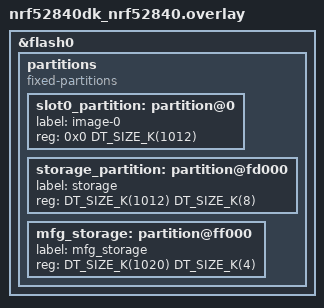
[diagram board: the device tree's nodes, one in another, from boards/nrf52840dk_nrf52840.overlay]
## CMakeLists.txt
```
#
# Copyright (c) 2026 Nordic Semiconductor ASA
#
# SPDX-License-Identifier: LicenseRef-Nordic-5-Clause
#

cmake_minimum_required(VERSION 3.20.0)

# Zephyr CMake project
find_package(Zephyr REQUIRED HINTS $ENV{ZEPHYR_BASE})
project(sidewalk_lr11xx_firmware_update)

# Source files
target_include_directories(app PRIVATE include)
target_sources(app PRIVATE
	src/main.c
	src/app.c
	src/lr11xx_firmware_update.c
)

if(CONFIG_SIDEWALK_SUBGHZ_RADIO_LR1110)
	target_include_directories(app PRIVATE
		${ZEPHYR_SIDEWALK_MODULE_DIR}/subsys/semtech/lr11xx
		${ZEPHYR_SIDEWALK_MODULE_DIR}/subsys/semtech/lr11xx/semtech
	)
	target_link_libraries(app PRIVATE
		smtc_lbm
		semtech_radio_ifc
	)
endif()

if(CONFIG_SIDEWALK_USE_PREBUILT_LIBRARIES)
	target_link_libraries(app PRIVATE sidewalk)
endif()
```

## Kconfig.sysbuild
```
#
# Copyright (c) 2023 Nordic Semiconductor ASA
#
# SPDX-License-Identifier: LicenseRef-Nordic-5-Clause
#

choice BOOTLOADER
	default BOOTLOADER_NONE
endchoice

source "${ZEPHYR_BASE}/share/sysbuild/Kconfig"
```

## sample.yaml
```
sample:
  name: LR11xx firmware update sample
  description: Sample for updating Semtech LR11xx transceiver firmware

common:
  sysbuild: true
  build_only: true
  tags:
    - Sidewalk
    - lr1110

tests:
  sample.lr11xx_firmware_update.lr1110:
    platform_allow:
      - nrf54l15dk/nrf54l15/cpuapp
    integration_platforms:
      - nrf54l15dk/nrf54l15/cpuapp
    extra_args:
      - SHIELD="simple_arduino_adapter;semtech_lr1110mb1xxs"

  sample.lr11xx_firmware_update.nrf_sidewalk_eb:
    platform_allow:
      - nrf54l15dk/nrf54l15/cpuapp
      - nrf54lm20dk/nrf54lm20a/cpuapp
      - nrf54lm20dk/nrf54lm20b/cpuapp
    integration_platforms:
      - nrf54l15dk/nrf54l15/cpuapp
      - nrf54lm20dk/nrf54lm20a/cpuapp
      - nrf54lm20dk/nrf54lm20b/cpuapp
    extra_args:
      - SHIELD="nrf_sidewalk_eb"
```

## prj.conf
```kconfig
#
# Copyright (c) 2026 Nordic Semiconductor ASA
#
# SPDX-License-Identifier: LicenseRef-Nordic-5-Clause
#

CONFIG_STATIC_INIT_GNU=y

# Sidewalk platform (radio PAL only, no DFU/bootloader)
CONFIG_SIDEWALK=y
CONFIG_SIDEWALK_DFU=n

# Log
CONFIG_LOG=y
CONFIG_LOG_PRINTK=y
CONFIG_LOG_BUFFER_SIZE=2048

# Stack and Heap
CONFIG_SYSTEM_WORKQUEUE_STACK_SIZE=4096

# Power Management
CONFIG_PM_DEVICE=y

# Debug
CONFIG_NCS_APPLICATION_BOOT_BANNER_STRING="LR11xx FW update"
CONFIG_RESET_ON_FATAL_ERROR=n
```

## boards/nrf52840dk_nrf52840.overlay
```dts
/*
 * Copyright (c) 2026 Nordic Semiconductor ASA
 *
 * SPDX-License-Identifier: LicenseRef-Nordic-5-Clause
 */

/delete-node/ &boot_partition;
/delete-node/ &slot0_partition;
/delete-node/ &slot1_partition;
/delete-node/ &storage_partition;

&flash0 {
	partitions {
		compatible = "fixed-partitions";
		#address-cells = <1>;
		#size-cells = <1>;

		slot0_partition: partition@0 {
			label = "image-0";
			reg = <0x0 DT_SIZE_K(1012)>;
		};

		storage_partition: partition@fd000 {
			label = "storage";
			reg = <DT_SIZE_K(1012) DT_SIZE_K(8)>;
		};

		mfg_storage: partition@ff000 {
			label = "mfg_storage";
			reg = <DT_SIZE_K(1020) DT_SIZE_K(4)>;
		};
	};
};
```

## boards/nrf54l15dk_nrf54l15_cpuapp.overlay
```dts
/*
 * Copyright (c) 2026 Nordic Semiconductor ASA
 *
 * SPDX-License-Identifier: LicenseRef-Nordic-5-Clause
 */

/delete-node/ &boot_partition;
/delete-node/ &slot0_partition;
/delete-node/ &slot1_partition;
/delete-node/ &storage_partition;

&cpuapp_rram {
	partitions {
		ranges;
		#address-cells = <1>;
		#size-cells = <1>;

		slot0_partition: partition@0 {
			compatible = "zephyr,mapped-partition";
			label = "image-0";
			reg = <0x0 DT_SIZE_K(1512)>;
		};

		storage_partition: partition@17a000 {
			compatible = "zephyr,mapped-partition";
			label = "storage";
			reg = <DT_SIZE_K(1512) DT_SIZE_K(8)>;
		};

		mfg_storage: partition@17c000 {
			compatible = "zephyr,mapped-partition";
			label = "mfg_storage";
			reg = <DT_SIZE_K(1520) DT_SIZE_K(4)>;
		};
	};
};
```

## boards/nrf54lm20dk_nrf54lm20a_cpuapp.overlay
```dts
/*
 * Copyright (c) 2026 Nordic Semiconductor ASA
 *
 * SPDX-License-Identifier: LicenseRef-Nordic-5-Clause
 */

/delete-node/ &boot_partition;
/delete-node/ &slot0_partition;
/delete-node/ &slot1_partition;
/delete-node/ &storage_partition;

&cpuapp_rram {
	partitions {
		ranges;
		#address-cells = <1>;
		#size-cells = <1>;

		slot0_partition: partition@0 {
			compatible = "zephyr,mapped-partition";
			label = "image-0";
			reg = <0x0 DT_SIZE_K(1904)>;
		};

		storage_partition: partition@1dc000 {
			compatible = "zephyr,mapped-partition";
			label = "storage";
			reg = <DT_SIZE_K(1904) DT_SIZE_K(8)>;
		};

		mfg_storage: partition@1de000 {
			compatible = "zephyr,mapped-partition";
			label = "mfg_storage";
			reg = <DT_SIZE_K(1912) DT_SIZE_K(4)>;
		};
	};
};
```

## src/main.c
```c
/*
 * Copyright (c) 2026 Nordic Semiconductor ASA
 *
 * SPDX-License-Identifier: LicenseRef-Nordic-5-Clause
 */

#include <app.h>

int main(void)
{
	app_start();
	return 0;
}
```

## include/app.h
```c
/*
 * Copyright (c) 2026 Nordic Semiconductor ASA
 *
 * SPDX-License-Identifier: LicenseRef-Nordic-5-Clause
 */

#ifndef APP_H_
#define APP_H_

/**
 * @brief Initialize platform and update LR11xx transceiver firmware.
 */
void app_start(void);

#endif /* APP_H_ */
```

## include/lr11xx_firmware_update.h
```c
/*!
 * @file	  lr11xx_firmware_update.h
 *
 * @brief	 LR11XX firmware update definition
 *
 * The Clear BSD License
 * Copyright Semtech Corporation 2021. All rights reserved.
 *
 * Redistribution and use in source and binary forms, with or without
 * modification, are permitted (subject to the limitations in the disclaimer
 * below) provided that the following conditions are met:
 *	 * Redistributions of source code must retain the above copyright
 *	   notice, this list of conditions and the following disclaimer.
 *	 * Redistributions in binary form must reproduce the above copyright
 *	   notice, this list of conditions and the following disclaimer in the
 *	   documentation and/or other materials provided with the distribution.
 *	 * Neither the name of the Semtech corporation nor the
 *	   names of its contributors may be used to endorse or promote products
 *	   derived from this software without specific prior written permission.
 *
 * NO EXPRESS OR IMPLIED LICENSES TO ANY PARTY'S PATENT RIGHTS ARE GRANTED BY
 * THIS LICENSE. THIS SOFTWARE IS PROVIDED BY THE COPYRIGHT HOLDERS AND
 * CONTRIBUTORS "AS IS" AND ANY EXPRESS OR IMPLIED WARRANTIES, INCLUDING, BUT
 * NOT LIMITED TO, THE IMPLIED WARRANTIES OF MERCHANTABILITY AND FITNESS FOR A
 * PARTICULAR PURPOSE ARE DISCLAIMED. IN NO EVENT SHALL SEMTECH CORPORATION BE
 * LIABLE FOR ANY DIRECT, INDIRECT, INCIDENTAL, SPECIAL, EXEMPLARY, OR
 * CONSEQUENTIAL DAMAGES (INCLUDING, BUT NOT LIMITED TO, PROCUREMENT OF
 * SUBSTITUTE GOODS OR SERVICES; LOSS OF USE, DATA, OR PROFITS; OR BUSINESS
 * INTERRUPTION) HOWEVER CAUSED AND ON ANY THEORY OF LIABILITY, WHETHER IN
 * CONTRACT, STRICT LIABILITY, OR TORT (INCLUDING NEGLIGENCE OR OTHERWISE)
 * ARISING IN ANY WAY OUT OF THE USE OF THIS SOFTWARE, EVEN IF ADVISED OF THE
 * POSSIBILITY OF SUCH DAMAGE.
 */

#ifndef LR11XX_FIRMWARE_UPDATE_H
#define LR11XX_FIRMWARE_UPDATE_H

#ifdef __cplusplus
extern "C" {
#endif

/*
 * -----------------------------------------------------------------------------
 * --- DEPENDENCIES ------------------------------------------------------------
 */

#include <stdint.h>

/*
 * -----------------------------------------------------------------------------
 * --- PUBLIC MACROS -----------------------------------------------------------
 */

/*
 * -----------------------------------------------------------------------------
 * --- PUBLIC CONSTANTS --------------------------------------------------------
 */

/*
 * -----------------------------------------------------------------------------
 * --- PUBLIC TYPES ------------------------------------------------------------
 */

typedef enum
{
	LR1110_FIRMWARE_UPDATE_TO_TRX,
	LR1110_FIRMWARE_UPDATE_TO_MODEM,
	LR1120_FIRMWARE_UPDATE_TO_TRX,
	LR1121_FIRMWARE_UPDATE_TO_TRX,
} lr11xx_fw_update_t;

typedef enum
{
	LR11XX_FW_UPDATE_OK			  = 0,
	LR11XX_FW_UPDATE_WRONG_CHIP_TYPE = 1,
	LR11XX_FW_UPDATE_ERROR		   = 2,
} lr11xx_fw_update_status_t;

/*
 * -----------------------------------------------------------------------------
 * --- PUBLIC FUNCTIONS PROTOTYPES ---------------------------------------------
 */

lr11xx_fw_update_status_t lr11xx_update_firmware( /*void* radio,*/ lr11xx_fw_update_t fw_update_direction,
												  uint32_t fw_expected, const uint32_t* buffer, uint32_t length );

#ifdef __cplusplus
}
#endif

#endif  // LR11XX_FIRMWARE_UPDATE_H

/* --- EOF ------------------------------------------------------------------ */
```

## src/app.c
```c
/*
 * Copyright (c) 2026 Nordic Semiconductor ASA
 *
 * SPDX-License-Identifier: LicenseRef-Nordic-5-Clause
 */

#include <app.h>
#include <app_mfg_config.h>
#include <app_subGHz_config.h>
#include <lr11xx_firmware_update.h>
#include <lr1110_transceiver_0401.h>
#include <sid_api.h>
#include <sid_error.h>
#include <sid_pal_common_ifc.h>
#include <sid_pal_radio_ifc.h>

#include <zephyr/logging/log.h>

LOG_MODULE_REGISTER(application, CONFIG_SIDEWALK_LOG_LEVEL);

static void radio_event_notifier(sid_pal_radio_events_t event)
{
	ARG_UNUSED(event);
}

static sid_pal_radio_rx_packet_t rx_packet;

static void radio_irq_handler(void)
{
}

void app_start(void)
{
	platform_parameters_t platform_parameters = {
		.mfg_store_region.addr_start = APP_MFG_CFG_FLASH_START,
		.mfg_store_region.addr_end = APP_MFG_CFG_FLASH_END,
#ifdef CONFIG_SIDEWALK_SUBGHZ_SUPPORT
		.platform_init_parameters.radio_cfg = get_radio_cfg(),
#else
#error "Sub-GHz support is required for LR11xx firmware update"
#endif
	};

	sid_error_t e = sid_platform_init(&platform_parameters);

	if (e != SID_ERROR_NONE) {
		LOG_ERR("Sidewalk platform init err: %d", e);
		return;
	}

	int32_t err = sid_pal_radio_init(radio_event_notifier, radio_irq_handler, &rx_packet);

	if (err != RADIO_ERROR_NONE) {
		LOG_ERR("sid_pal_radio_init() failed: %d", err);
		/* This might fail due to too old firmware. Continue anyway. */
	}

	const lr11xx_fw_update_status_t status =
		lr11xx_update_firmware(LR11XX_FIRMWARE_UPDATE_TO, LR11XX_FIRMWARE_VERSION,
				       lr11xx_firmware_image, LR11XX_FIRMWARE_IMAGE_SIZE);

	switch (status) {
	case LR11XX_FW_UPDATE_OK:
		LOG_INF("Expected firmware running");
		LOG_INF("Flash another application (for example sid_end_device) to continue");
		break;
	case LR11XX_FW_UPDATE_WRONG_CHIP_TYPE:
		LOG_ERR("Wrong chip type");
		break;
	case LR11XX_FW_UPDATE_ERROR:
		LOG_ERR("Firmware update failed - please retry");
		break;
	}
}
```

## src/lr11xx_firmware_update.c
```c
/*
 * The Clear BSD License
 * Copyright Semtech Corporation 2021. All rights reserved.
 * Copyright (c) 2026 Nordic Semiconductor ASA.
 *
 * Redistribution and use in source and binary forms, with or without
 * modification, are permitted (subject to the limitations in the disclaimer
 * below) provided that the following conditions are met:
 *	 * Redistributions of source code must retain the above copyright
 *	   notice, this list of conditions and the following disclaimer.
 *	 * Redistributions in binary form must reproduce the above copyright
 *	   notice, this list of conditions and the following disclaimer in the
 *	   documentation and/or other materials provided with the distribution.
 *	 * Neither the name of the Semtech corporation nor the
 *	   names of its contributors may be used to endorse or promote products
 *	   derived from this software without specific prior written permission.
 *
 * NO EXPRESS OR IMPLIED LICENSES TO ANY PARTY'S PATENT RIGHTS ARE GRANTED BY
 * THIS LICENSE. THIS SOFTWARE IS PROVIDED BY THE COPYRIGHT HOLDERS AND
 * CONTRIBUTORS "AS IS" AND ANY EXPRESS OR IMPLIED WARRANTIES, INCLUDING, BUT
 * NOT LIMITED TO, THE IMPLIED WARRANTIES OF MERCHANTABILITY AND FITNESS FOR A
 * PARTICULAR PURPOSE ARE DISCLAIMED. IN NO EVENT SHALL SEMTECH CORPORATION BE
 * LIABLE FOR ANY DIRECT, INDIRECT, INCIDENTAL, SPECIAL, EXEMPLARY, OR
 * CONSEQUENTIAL DAMAGES (INCLUDING, BUT NOT LIMITED TO, PROCUREMENT OF
 * SUBSTITUTE GOODS OR SERVICES; LOSS OF USE, DATA, OR PROFITS; OR BUSINESS
 * INTERRUPTION) HOWEVER CAUSED AND ON ANY THEORY OF LIABILITY, WHETHER IN
 * CONTRACT, STRICT LIABILITY, OR TORT (INCLUDING NEGLIGENCE OR OTHERWISE)
 * ARISING IN ANY WAY OUT OF THE USE OF THIS SOFTWARE, EVEN IF ADVISED OF THE
 * POSSIBILITY OF SUCH DAMAGE.
 */

#include <lr11xx_firmware_update.h>

#include <app_subGHz_config.h>
#include <halo_lr11xx_radio.h>
#include <lr11xx_bootloader.h>
#include <lr11xx_system.h>
#include <sid_pal_delay_ifc.h>
#include <sid_pal_gpio_ifc.h>

#include <zephyr/logging/log.h>

LOG_MODULE_REGISTER(fwup, CONFIG_SIDEWALK_LOG_LEVEL);

#define LR11XX_TYPE_PRODUCTION_MODE 0xDF
#define RESET_DELAY_US              500000
#define BUSY_DIR_IN_DELAY_US        100000

static bool lr11xx_is_chip_in_production_mode(uint8_t type)
{
	return type == LR11XX_TYPE_PRODUCTION_MODE;
}

static bool lr11xx_is_fw_compatible_with_chip(lr11xx_fw_update_t update, uint16_t bootloader_version)
{
	if (((update == LR1110_FIRMWARE_UPDATE_TO_TRX) ||
	     (update == LR1110_FIRMWARE_UPDATE_TO_MODEM)) &&
	    (bootloader_version != 0x6500)) {
		return false;
	}

	if ((update == LR1120_FIRMWARE_UPDATE_TO_TRX) && (bootloader_version != 0x2000)) {
		return false;
	}

	if ((update == LR1121_FIRMWARE_UPDATE_TO_TRX) && (bootloader_version != 0x2100)) {
		return false;
	}

	return true;
}

lr11xx_fw_update_status_t lr11xx_update_firmware(lr11xx_fw_update_t fw_update_direction,
						 uint32_t fw_expected,
						 const uint32_t *buffer,
						 uint32_t length)
{
	lr11xx_bootloader_version_t version_bootloader;
	void *drv_ctx;
	const radio_lr11xx_device_config_t *cfg =
		(const radio_lr11xx_device_config_t *)get_radio_cfg();
	sid_error_t gpio_err;

	LOG_INF("Reset the chip");

	gpio_err = sid_pal_gpio_set_direction(cfg->gpios.radio_busy,
					      SID_PAL_GPIO_DIRECTION_OUTPUT);
	if (gpio_err != SID_ERROR_NONE) {
		LOG_ERR("Failed to set BUSY pin direction to output: %d", gpio_err);
		return LR11XX_FW_UPDATE_ERROR;
	}

	gpio_err = sid_pal_gpio_write(cfg->gpios.radio_busy, 0);
	if (gpio_err != SID_ERROR_NONE) {
		LOG_ERR("Failed to drive BUSY pin low: %d", gpio_err);
		return LR11XX_FW_UPDATE_ERROR;
	}

	drv_ctx = lr11xx_get_drv_ctx();
	if (lr11xx_system_reset(drv_ctx) != LR11XX_STATUS_OK) {
		LOG_ERR("lr11xx_system_reset failed");
		return LR11XX_FW_UPDATE_ERROR;
	}

	sid_pal_delay_us(RESET_DELAY_US);

	gpio_err = sid_pal_gpio_set_direction(cfg->gpios.radio_busy,
					      SID_PAL_GPIO_DIRECTION_INPUT);
	if (gpio_err != SID_ERROR_NONE) {
		LOG_ERR("Failed to set BUSY pin direction to input: %d", gpio_err);
		return LR11XX_FW_UPDATE_ERROR;
	}

	sid_pal_delay_us(BUSY_DIR_IN_DELAY_US);

	LOG_INF("Reset done");

	if (lr11xx_bootloader_get_version(drv_ctx, &version_bootloader) != LR11XX_STATUS_OK) {
		LOG_ERR("lr11xx_bootloader_get_version failed");
		return LR11XX_FW_UPDATE_ERROR;
	}

	LOG_INF("Chip in bootloader mode");
	LOG_INF(" - Chip type               = 0x%02X (0xDF for production)",
		version_bootloader.type);
	LOG_INF(" - Chip hardware version   = 0x%02X (0x22 for V2C)", version_bootloader.hw);
	LOG_INF(" - Chip bootloader version = 0x%04X", version_bootloader.fw);

	if (!lr11xx_is_chip_in_production_mode(version_bootloader.type)) {
		LOG_ERR("Chip is not in production mode");
		return LR11XX_FW_UPDATE_WRONG_CHIP_TYPE;
	}

	if (!lr11xx_is_fw_compatible_with_chip(fw_update_direction, version_bootloader.fw)) {
		LOG_ERR("Incompatible firmware for chip bootloader version");
		return LR11XX_FW_UPDATE_WRONG_CHIP_TYPE;
	}

	LOG_INF("Start flash erase");

	if (lr11xx_bootloader_erase_flash(drv_ctx) != LR11XX_STATUS_OK) {
		LOG_ERR("lr11xx_bootloader_erase_flash failed");
		return LR11XX_FW_UPDATE_ERROR;
	}

	LOG_INF("Flash erase done");

	LOG_INF("Start flashing firmware (%u bytes)", length);

	if (lr11xx_bootloader_write_flash_encrypted_full(drv_ctx, 0, buffer, length) !=
	    LR11XX_STATUS_OK) {
		LOG_ERR("lr11xx_bootloader_write_flash_encrypted_full failed");
		return LR11XX_FW_UPDATE_ERROR;
	}

	LOG_INF("Flashing done");

	LOG_INF("Rebooting");

	if (lr11xx_bootloader_reboot(drv_ctx, false) != LR11XX_STATUS_OK) {
		LOG_ERR("lr11xx_bootloader_reboot failed");
		return LR11XX_FW_UPDATE_ERROR;
	}

	LOG_INF("Reboot done");

	switch (fw_update_direction) {
	case LR1110_FIRMWARE_UPDATE_TO_TRX:
	case LR1120_FIRMWARE_UPDATE_TO_TRX:
	case LR1121_FIRMWARE_UPDATE_TO_TRX: {
		lr11xx_system_version_t version_trx;
		lr11xx_system_uid_t uid;

		if (lr11xx_system_get_version(drv_ctx, &version_trx) != LR11XX_STATUS_OK) {
			LOG_ERR("lr11xx_system_get_version failed");
			return LR11XX_FW_UPDATE_ERROR;
		}

		LOG_INF("Chip in transceiver mode");
		LOG_INF(" - Chip type               = 0x%02X", version_trx.type);
		LOG_INF(" - Chip hardware version   = 0x%02X", version_trx.hw);
		LOG_INF(" - Chip firmware version   = 0x%04X", version_trx.fw);

		if (lr11xx_system_read_uid(drv_ctx, uid) != LR11XX_STATUS_OK) {
			LOG_ERR("lr11xx_system_read_uid failed");
			return LR11XX_FW_UPDATE_ERROR;
		}

		if (version_trx.fw == fw_expected) {
			return LR11XX_FW_UPDATE_OK;
		}

		LOG_ERR("Unexpected firmware version 0x%04X (expected 0x%04X)", version_trx.fw,
			fw_expected);
		return LR11XX_FW_UPDATE_ERROR;
	}
	case LR1110_FIRMWARE_UPDATE_TO_MODEM:
		LOG_ERR("LR1110 modem firmware update is not supported");
		return LR11XX_FW_UPDATE_ERROR;
	default:
		LOG_ERR("Unsupported firmware update direction: %d", fw_update_direction);
		return LR11XX_FW_UPDATE_ERROR;
	}
}
```
